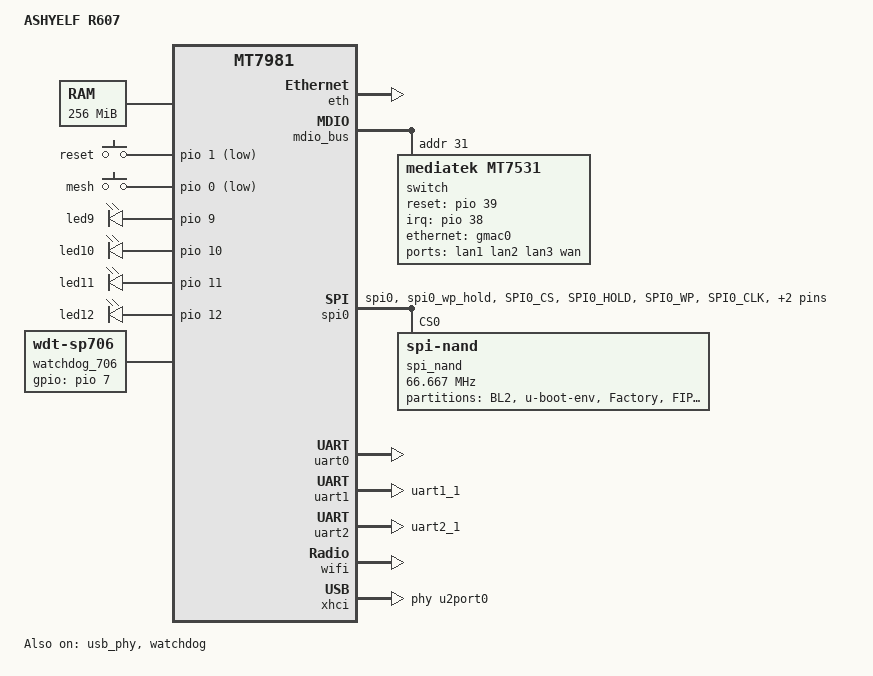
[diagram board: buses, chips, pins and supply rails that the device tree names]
// SPDX-License-Identifier: GPL-2.0-or-later OR MIT
/*
 * Copyright (C) 2023 Tianling Shen <cnsztl@immortalwrt.org>
 */

/dts-v1/;
#include <dt-bindings/gpio/gpio.h>
#include <dt-bindings/input/input.h>
#include <dt-bindings/leds/common.h>

#include "mt7981b.dtsi"

/ {
	model = "ASHYELF R607";
	compatible = "ashyelf,r607", "mediatek,mt7981";

	aliases {
		watchdog0 = &watchdog;
		watchdog9 = &watchdog_706;
	};

	chosen: chosen {
			bootargs = "console=ttyS0,115200n8 loglevel=6  \
				earlycon=uart8250,mmio32,0x11002000";
	};

	memory {
		reg = <0 0x40000000 0 0x10000000>;
	};

	gpio-keys {
		compatible = "gpio-keys";

		button-reset {
			label = "reset";
			linux,code = <KEY_RESTART>;
			gpios = <&pio 1 GPIO_ACTIVE_LOW>;
		};

		button-mesh {
			label = "mesh";
			linux,code = <BTN_9>;
			linux,input-type = <EV_SW>;
			gpios = <&pio 0 GPIO_ACTIVE_LOW>;
		};
	};

	leds {
		compatible = "gpio-leds";

		bd_led1: led-1 {
			label = "led9";
			gpios = <&pio 9 GPIO_ACTIVE_HIGH>;
		};

		bd_led2: led-2 {
			label = "led10";
			gpios = <&pio 10 GPIO_ACTIVE_HIGH>;
		};

		bd_led3: led-3 {
			label = "led11";
			gpios = <&pio 11 GPIO_ACTIVE_HIGH>;
		};

		bd_led4: led-4 {
			label = "led12";
			gpios = <&pio 12 GPIO_ACTIVE_HIGH>;
		};

	};

	watchdog_706: watchdog-706 {
		compatible = "linux,wdt-sp706";
		always-enabled;
		always-running;
		gpios = <&pio 7  GPIO_ACTIVE_HIGH>;
		hw_algo = "toggle";
		hw_margin_ms = <500>;
		hw_timer_times = <8>;
		status = "okay";
	};
};

&afe {
	status = "disabled";
};

&eth {
	status = "okay";

	gmac0: mac@0 {
		compatible = "mediatek,eth-mac";
		reg = <0>;
		phy-mode = "2500base-x";

		nvmem-cell-names = "mac-address";
		nvmem-cells = <&macaddr_factory_24 0>;
		fixed-link {
			speed = <2500>;
			full-duplex;
			pause;
		};
	};

	/*
	 * gmac1 + int_gbe_phy: unused on R607 (all RJ45 via MT7531).
	 * To enable: delete status = "disabled" below (no fixed-link with phy-handle).
	 */
	gmac1: mac@1 {
		status = "disabled";
		compatible = "mediatek,eth-mac";
		reg = <1>;
		phy-mode = "gmii";
		phy-handle = <&int_gbe_phy>;

		nvmem-cell-names = "mac-address";
		nvmem-cells = <&macaddr_factory_2a 0>;
	};
};

&mdio_bus {
	switch: switch@1f {
		compatible = "mediatek,mt7531";
		reg = <31>;
		reset-gpios = <&pio 39 GPIO_ACTIVE_HIGH>;
		interrupt-controller;
		#interrupt-cells = <1>;
		interrupt-parent = <&pio>;
		interrupts = <38 IRQ_TYPE_LEVEL_HIGH>;
	};
};

&spi0 {
	pinctrl-names = "default";
	pinctrl-0 = <&spi0_flash_pins>;
	status = "okay";

	spi_nand@0 {
		compatible = "spi-nand";
		#address-cells = <1>;
		#size-cells = <1>;
		reg = <0>;

		spi-max-frequency = <66666666>;
		spi-tx-bus-width = <4>;
		spi-rx-bus-width = <4>;

		partitions {
			compatible = "fixed-partitions";
			#address-cells = <1>;
			#size-cells = <1>;

			partition@0 {
				label = "BL2";
				reg = <0x00000 0x0100000>;
				read-only;
			};

			partition@100000 {
				label = "u-boot-env";
				reg = <0x100000 0x80000>;
			};

			factory: partition@180000 {
				label = "Factory";
				reg = <0x180000 0x200000>;

				compatible = "nvmem-cells";
				nvmem-layout {
					compatible = "fixed-layout";
					#address-cells = <1>;
					#size-cells = <1>;

					macaddr_factory_24: macaddr@24 {
						compatible = "mac-base";
						reg = <0x24 0x6>;
						#nvmem-cell-cells = <1>;
					};

					macaddr_factory_2a: macaddr@2a {
						compatible = "mac-base";
						reg = <0x2a 0x6>;
						#nvmem-cell-cells = <1>;
					};
				};
			};

			partition@380000 {
					label = "FIP";
					reg = <0x380000 0x200000>;
			};

			partition@580000 {
					label = "ubi";
					reg = <0x580000 0x02000000>;
			};

			partition@2580000 {
					label = "ubi2";
					reg = <0x2580000 0x02000000>;
			};

			Fconfig: partition@4580000 {
					label = "Fconfig";
					reg = <0x4580000 0x1000000>;
			};

			OEM: partition@5580000 {
					label = "OEM";
					reg = <0x5580000 0x1000000>;
			};

			partition@6580000 {
					label = "reserve";
					reg = <0x6580000 0x8A80000>;
			};

		};
	};
};

&switch {
	ports {
		#address-cells = <1>;
		#size-cells = <0>;

		port@0 {
			reg = <0>;
			label = "lan1";
		};

		port@1 {
			reg = <1>;
			label = "lan2";
		};

		port@2 {
			reg = <2>;
			label = "lan3";
		};

		port@3 {
			reg = <3>;
			label = "wan";
		};

		port@6 {
			reg = <6>;
			ethernet = <&gmac0>;
			phy-mode = "2500base-x";

			fixed-link {
				speed = <2500>;
				full-duplex;
				pause;
			};
		};
	};
};

&pio {
        pcm_pins: pcm-pins-g0 {
                mux {
                        function = "pcm";
                        groups = "pcm";
                };
        };


	spi0_flash_pins: spi0-pins {
		mux {
			function = "spi";
			groups = "spi0", "spi0_wp_hold";
		};

		conf-pu {
			pins = "SPI0_CS", "SPI0_HOLD", "SPI0_WP";
			drive-strength = <MTK_DRIVE_8mA>;
			bias-pull-up = <MTK_PUPD_SET_R1R0_11>;
		};

		conf-pd {
			pins = "SPI0_CLK", "SPI0_MOSI", "SPI0_MISO";
			drive-strength = <MTK_DRIVE_8mA>;
			bias-pull-down = <MTK_PUPD_SET_R1R0_11>;
		};
	};

	uart1_pins: uart1-pins-g1 {
                mux {
                        function = "uart";
                        groups = "uart1_1";
                };
        };

	uart2_pins: uart2-pins-g1 {
		mux {
                        function = "uart";
                        groups = "uart2_1";
                };
        };

};


&uart0 {
	status = "okay";
};

&uart1 {
	pinctrl-names = "default";
	pinctrl-0 = <&uart1_pins>;
	status = "okay";
};

&uart2 {
	pinctrl-names = "default";
	pinctrl-0 = <&uart2_pins>;
	status = "okay";
};

&usb_phy {
	status = "okay";
};

&watchdog {
	status = "okay";
};

&wifi {
	mediatek,mtd-eeprom = <&factory 0x0>;
	status = "okay";
};

&xhci {
	mediatek,u3p-dis-msk = <0x0>;
	phys = <&u2port0 PHY_TYPE_USB2>,
	       <&u3port0 PHY_TYPE_USB3>;
	status = "okay";
};
